# max32572 register map
Vendor: Maxim-Integrated; Series: ARMCM4; File version: 1.0
CPU: CM4 r2p1, little endian, MPU, FPU, 3 interrupt priority bits
Registers are 32-bit, read-write, reset 0x0 unless marked. A register's access mark holds for its fields unless they carry their own. Offsets are from the block's base; [hi:lo] are bit positions; {n}, {i} and the like mark numbered series.

## OTP — One-Time Programmable (OTP) Memory Controller.
Base 0x40041000
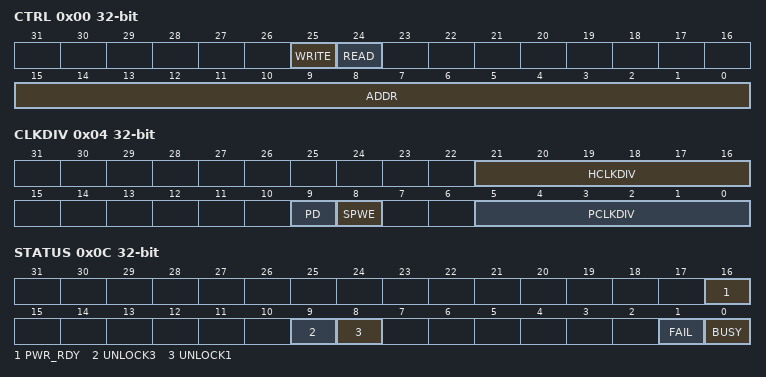
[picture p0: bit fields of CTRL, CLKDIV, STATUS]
0x00 CTRL — OTP Control Register.
  [25] WRITE — Program Operation. Setting this bit starts a write operation from the OTP location specified in the ADDR field.
  [24] READ — Read Operation. Setting this bit starts a read operation from the OTP.
    0=No operation; 1=start (Initiate program operation.)
  [15:0] ADDR — Address of the OTP 32 bit value.
0x04 CLKDIV — OTP Clock Divide Register.
  [21:16] HCLKDIV — Clock Divider. The input clock, HCLK, is divided for generating OTP pwr on and down timing signals.
  [9] PD — Power Down OTP. OTP controller will generate power up and down signals for control pins.
  [8] SPWE — Smart PWE. If programmed value is 1, don't assert PWE.
  [5:0] PCLKDIV — Clock Divider. The input clock, PCLK, is divided for generating OTP timing signals.
    1=DIV2 (Divide by 2); 3=DIV4 (Divide by 4); 7=DIV8 (Divide by 8); 15=DIV16 (Divide by 16); 31=DIV32 (Divide by 32)
0x08 RDATA — GPIO Clear Function Enable Register. Writing a 1 to one or more bits in this register clears the bits in the same positions in GPIO_EN to 0, without affecting other bits in that register.
  [31:0] DATA — OTP Read Data.
0x0C STATUS — OTP Status Register.
  [16] PWR_RDY — OTP Power On Status.
  [9] UNLOCK3 — Unlock3 Flag. This bit indicates that 3 words unlock process is complete.
  [8] UNLOCK1 — Unlock1 Flag. This bit indicates that 1st password was entered, and the user block is enabled for OTP programming.
  [1] FAIL — OTP Failed Flag. This bit indicates whether OTP programming has failed. OTP programming fails if the controller accesses a 32 bit location that has not been previously programmed.
  [0] BUSY — OTP Busy Flag. This bit indicates whether the OTP controller is working a read or write operation.
0x30 WDATA — OTP Write Data Register.
  [31:0] DATA — Write Data.
0x3C ACTRL0 — Access Control for user block.
  [31:0] ADATA — User Block Access Control.
0x40 ACTRL1 — Access Control for sys and user block.
  [31:0] ADATA — System Info Block Access Data.

## PT — Pulse Train
Base 0x4003C020
Same registers: PT8 ?, PT1 0x4003C030, PT2 0x4003C040, PT3 0x4003C050, PT4 0x4003C060, PT5 0x4003C070, PT6 0x4003C080, PT7 0x4003C090
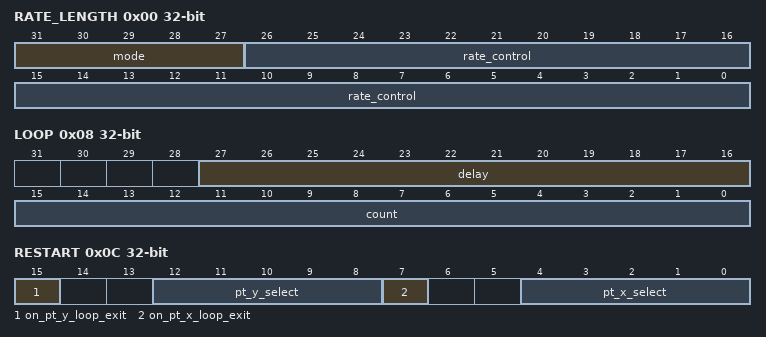
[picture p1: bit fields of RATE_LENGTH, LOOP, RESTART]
0x00 RATE_LENGTH — Pulse Train Configuration
  [31:27] mode — Pulse Train Output Mode/Train Length
    0=32_BIT (Pulse train, 32 bit pattern.); 1=SQUARE_WAVE (Square wave mode.); {v}={v}_BIT (Pulse train, {v} bit pattern.) (v=2..31)
  [26:0] rate_control — Pulse Train Enable and Rate Control. Set to 0 to disable the Pulse Train.
0x04 TRAIN — Write the repeating bit pattern that is shifted out, LSB first, when configured in Pulse Train mode. See PT_RATE_LENGTH.mode for setting the length.
0x08 LOOP — Pulse Train Loop Count
  [27:16] delay — Delay between loops of the Pulse Train in PT Peripheral Clock cycles
  [15:0] count — Number of loops for this pulse train to repeat.
0x0C RESTART — Pulse Train Auto-Restart Configuration.
  [15] on_pt_y_loop_exit — Enable Auto-Restart on PT Y Loop Exit
  [12:8] pt_y_select — Auto-Restart PT Y Select
  [7] on_pt_x_loop_exit — Enable Auto-Restart on PT X Loop Exit
  [4:0] pt_x_select — Auto-Restart PT X Select

## PTG — Pulse Train Generation
Base 0x4003C000
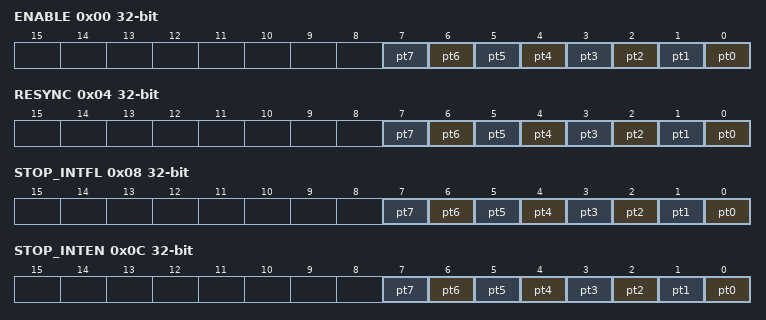
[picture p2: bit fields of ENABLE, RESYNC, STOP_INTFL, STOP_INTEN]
0x00 ENABLE — Global Enable/Disable Controls for All Pulse Trains
  [n] pt{n} (n=0..7) — Enable/Disable control for PT{n}
0x04 RESYNC — Global Resync (All Pulse Trains) Control
  [n] pt{n} (n=0..7) — Resync control for PT{n}
0x08 STOP_INTFL — Pulse Train Stop Interrupt Flags
  [n] pt{n} (n=0..7) — Pulse Train {n} Stopped Interrupt Flag
0x0C STOP_INTEN — Pulse Train Stop Interrupt Enable/Disable
  [n] pt{n} (n=0..7) — Pulse Train {n} Stopped Interrupt Enable/Disable
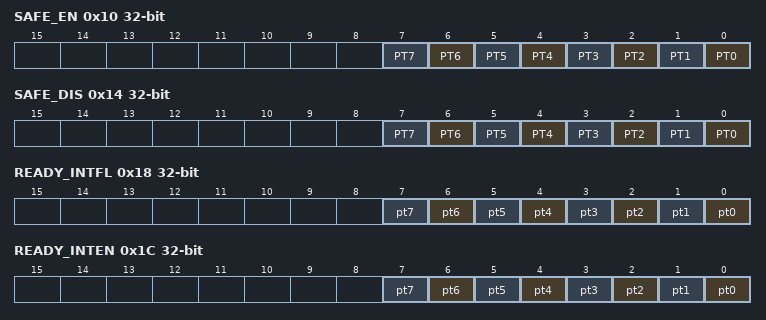
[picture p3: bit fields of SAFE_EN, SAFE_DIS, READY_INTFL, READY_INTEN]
0x10 SAFE_EN wo — Pulse Train Global Safe Enable.
  [n] PT{n} (n=0..7)
0x14 SAFE_DIS wo — Pulse Train Global Safe Disable.
  [n] PT{n} (n=0..7)
0x18 READY_INTFL — Pulse Train Ready Interrupt Flags
  [n] pt{n} (n=0..7) — Pulse Train {n} Ready Interrupt Flag
0x1C READY_INTEN — Pulse Train Ready Interrupt Enable/Disable
  [n] pt{n} (n=0..7) — Pulse Train {n} Ready Interrupt Enable/Disable
